# CTRL_MODULE_CORE register map
Vendor: Texas Instruments
Peripheral module from a debugger description file (folder omap5430_ES2_PUBLIC).
Registers are 32-bit, read-only, reset 0x0 unless marked. A register's access mark holds for its fields unless they carry their own. Offsets are as the file gives them; lines under a group give offsets from that group; [hi:lo] are bit positions; {n}, {i} and the like mark numbered series; 'fields as' and 'values as' point back to an identical list; <NAME> marks a mode.

## CTRL_MODULE_CORE (part 1 of 2)
0x00 CONTROL_CORE_REVISION reset not defined — Control module revision identifier Access conditions. Read: unrestricted, Write: unrestricted
  [31:0] REVISON — IP Revision enum=hl_scheme . enum=legacy_scheme .
0x04 CONTROL_CORE_HWINFO — Information about the IP module hardware configuration i.e. typically the module HDL generics (if any). Access conditions. Read: unrestricted, Write: unrestricted
  [31:0] IP_HWINFO — IP-module dependent
0x10 CONTROL_CORE_SYSCONFIG access per field reset 0x8 — Access conditions. Read: unrestricted, Write: unrestricted
  [3:2] IP_SYSCONFIG_IDLEMODE rw — RESERVED (not used).
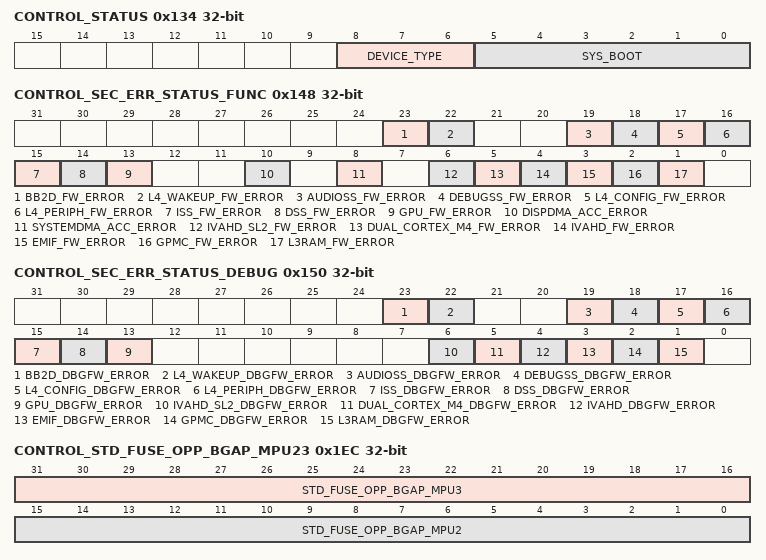
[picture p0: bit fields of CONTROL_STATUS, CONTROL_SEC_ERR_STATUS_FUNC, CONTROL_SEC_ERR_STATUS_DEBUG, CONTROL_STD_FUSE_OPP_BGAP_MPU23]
0x134 CONTROL_STATUS — Control Module Status Register Access conditions. Read: unrestricted, Write: unrestricted
  [8:6] DEVICE_TYPE — Device type captured at reset time Device type value sampled at power-on reset. . .
    3=dev_gp (General Purpose (GP))
  [5:0] SYS_BOOT — Sys.Boot pins state captured at reset time Sys.Boot pin values sampled at power-on reset
0x148 CONTROL_SEC_ERR_STATUS_FUNC — Firewall Error Status functional Register Access conditions. Read Only
  [23] BB2D_FW_ERROR — BB2D firewall
    0=no_bb2d_fw_error (No error from firewall); 1=bb2d_fw_error (Error from firewall)
  [22] L4_WAKEUP_FW_ERROR — L4 wakeup firewall
    0=no_l4wkup_fw_error (No error from firewall); 1=l4wkup_fw_error (Error from firewall)
  [19] AUDIOSS_FW_ERROR — AUDIOSS firewall
    0=no_audioss_init_fw_err (No error from firewall); 1=audioss_init_fw_err (Error from firewall)
  [18] DEBUGSS_FW_ERROR — DebugSS firewall
    0=no_debugss_fw_err (No error from firewall); 1=debugss_fw_err (Error from firewall)
  [17] L4_CONFIG_FW_ERROR — L4 config firewall
    0=no_l4config_fw_err (No error from firewall); 1=l4config_fw_err (Error from firewall)
  [16] L4_PERIPH_FW_ERROR — L4 periph firewall
    0=no_l4periph_fw_err (No error from firewall); 1=l4periph_fw_err (Error from firewall)
  [15] ISS_FW_ERROR — ISS firewall
    0=no_iss_fw_err (No error from firewall); 1=iss_fw_err (Error from firewall)
  [14] DSS_FW_ERROR — DSS firewall
    0=no_dss_fw_err (No error from firewall); 1=dss_fw_err (Error from firewall)
  [13] GPU_FW_ERROR — GPU firewall
    0=no_gpu_fw_err (No error from firewall); 1=gpu_fw_err (Error from firewall)
  [10] DISPDMA_ACC_ERROR — DISPDMA target firewall
    0=no_dispdma_target_fw_err (No error from firewall); 1=dispdma_target_fw_err (Error from firewall)
  [8] SYSTEMDMA_ACC_ERROR — SYSTEMDMA target firewall
    0=no_systemdma_target_fw_err (No error from firewall); 1=systemdma_target_fw_err (Error from firewall)
  [6] IVAHD_SL2_FW_ERROR — IVAHD SL2 firewall
    0=no_ivahd_sl2_fw_err (No error from firewall); 1=ivahd_sl2_fw_err (Error from firewall)
  [5] DUAL_CORTEX_M4_FW_ERROR — Dual Cortex M4 firewall
    0=no_ducati_fw_err (No error from firewall); 1=ducati_fw_err (Error from firewall)
  [4] IVAHD_FW_ERROR — IVAHD firewall
    0=no_ivahd_fw_err (No error from firewall); 1=ivahd_fw_err (Error from firewall)
  [3] EMIF_FW_ERROR — EMIF firewall
    0=no_emif_fw_err (No error from firewall); 1=emif_fw_err (Error from firewall)
  [2] GPMC_FW_ERROR — GPMC firewall
    0=no_gpmc_fw_err (No error from firewall); 1=gpmc_fw_err (Error from firewall)
  [1] L3RAM_FW_ERROR — L3RAM firewall
    0=no_l3ram_fw_err (No error from firewall); 1=l3ram_fw_err (Error from firewall)
0x150 CONTROL_SEC_ERR_STATUS_DEBUG access not given — Firewall Error Status debug Register. Access conditions. Read: unrestricted, Write: unrestricted
  [23] BB2D_DBGFW_ERROR — BB2D debug firewall (access RW W1toClr)
    values as CONTROL_SEC_ERR_STATUS_FUNC.BB2D_FW_ERROR
  [22] L4_WAKEUP_DBGFW_ERROR — L4 wakeup debug firewall (access RW W1toClr)
    values as CONTROL_SEC_ERR_STATUS_FUNC.L4_WAKEUP_FW_ERROR
  [19] AUDIOSS_DBGFW_ERROR — AUDIOSS debug firewall (access RW W1toClr)
    values as CONTROL_SEC_ERR_STATUS_FUNC.AUDIOSS_FW_ERROR
  [18] DEBUGSS_DBGFW_ERROR — DebugSS debug firewall (access RW W1toClr)
    values as CONTROL_SEC_ERR_STATUS_FUNC.DEBUGSS_FW_ERROR
  [17] L4_CONFIG_DBGFW_ERROR — L4 config debug firewall (access RW W1toClr)
    values as CONTROL_SEC_ERR_STATUS_FUNC.L4_CONFIG_FW_ERROR
  [16] L4_PERIPH_DBGFW_ERROR — L4 periph debug firewall (access RW W1toClr)
    values as CONTROL_SEC_ERR_STATUS_FUNC.L4_PERIPH_FW_ERROR
  [15] ISS_DBGFW_ERROR — ISS debug firewall (access RW W1toClr)
    values as CONTROL_SEC_ERR_STATUS_FUNC.ISS_FW_ERROR
  [14] DSS_DBGFW_ERROR — DSS debug firewall (access RW W1toClr)
    values as CONTROL_SEC_ERR_STATUS_FUNC.DSS_FW_ERROR
  [13] GPU_DBGFW_ERROR — GPU debug firewall (access RW W1toClr)
    values as CONTROL_SEC_ERR_STATUS_FUNC.GPU_FW_ERROR
  [6] IVAHD_SL2_DBGFW_ERROR — IVAHD SL2 debug firewall (access RW W1toClr)
    values as CONTROL_SEC_ERR_STATUS_FUNC.IVAHD_SL2_FW_ERROR
  [5] DUAL_CORTEX_M4_DBGFW_ERROR — Dual Cortex M4 debug firewall (access RW W1toClr)
    values as CONTROL_SEC_ERR_STATUS_FUNC.DUAL_CORTEX_M4_FW_ERROR
  [4] IVAHD_DBGFW_ERROR — IVAHD debug firewall (access RW W1toClr)
    values as CONTROL_SEC_ERR_STATUS_FUNC.IVAHD_FW_ERROR
  [3] EMIF_DBGFW_ERROR — EMIF debug firewall (access RW W1toClr)
    values as CONTROL_SEC_ERR_STATUS_FUNC.EMIF_FW_ERROR
  [2] GPMC_DBGFW_ERROR — GPMC debug firewall (access RW W1toClr)
    values as CONTROL_SEC_ERR_STATUS_FUNC.GPMC_FW_ERROR
  [1] L3RAM_DBGFW_ERROR — L3RAM debug firewall (access RW W1toClr)
    values as CONTROL_SEC_ERR_STATUS_FUNC.L3RAM_FW_ERROR
0x15C CONTROL_FORCEWRNP access per field — FORCE WRITE NON POSTED Access conditions. Read: unrestricted, Write: unrestricted
  [0] MPU_FORCEWRNP rw — Force mpu write non posted
    0=disable force wrnp; 1=enable (force wrnp)
{0x194+4i} CONTROL_STD_FUSE_OPP_VDD_MM_{i} (i=0..5) — Standard Fuse OPP VDD_MM [{32i+31}:{32i}]. Register shows part of the chip eFuse configuration on the OCP interface. Reading at the address of one of these registers provides a direct view into a part of the eFuse chain. Access conditions. Read: unrestricted, Write: unrestricted
  [31:0] STD_FUSE_OPP_VDD_MM_{i}
{0x1AC+4i} CONTROL_STD_FUSE_OPP_VDD_MPU_{i} (i=0..7) — Standard Fuse OPP VDD_MPU [{32i+31}:{32i}]. Register shows part of the chip eFuse configuration on the OCP interface. Reading at the address of one of these registers provides a direct view into a part of the eFuse chain. Access conditions. Read: unrestricted, Write: unrestricted
  [31:0] STD_FUSE_OPP_VDD_MPU_{i}
{0x1CC+4i} CONTROL_STD_FUSE_OPP_VDD_CORE_{i} (i=0..4) — Standard Fuse OPP VDD_CORE [{32i+31}:{32i}]. Register shows part of the chip eFuse configuration on the OCP interface. Reading at the address of one of these registers provides a direct view into a part of the eFuse chain. Access conditions. Read: unrestricted, Write: unrestricted
  [31:0] STD_FUSE_OPP_VDD_CORE_{i}
0x1E0 CONTROL_STD_FUSE_OPP_BGAP_MM — Standard Fuse OPP BGAP MM. Register shows part of the chip eFuse configuration. Reading at the address of one of these registers provides a direct view into a part of the eFuse chain. Access conditions. Read: unrestricted, Write: unrestricted
  [31:0] STD_FUSE_OPP_BGAP_MM
0x1E4 CONTROL_STD_FUSE_OPP_BGAP_MPU — Standard Fuse OPP BGAP BGAP. Register shows part of the chip eFuse configuration. Reading at the address of one of these registers provides a direct view into a part of the eFuse chain. Access conditions. Read: unrestricted, Write: unrestricted
  [31:0] STD_FUSE_OPP_BGAP_MPU
0x1E8 CONTROL_STD_FUSE_OPP_BGAP_CORE — Standard Fuse OPP BGAP CORE. Register shows part of the chip eFuse configuration. Reading at the address of one of these registers provides a direct view into a part of the eFuse chain. Access conditions. Read: unrestricted, Write: unrestricted
  [31:0] STD_FUSE_OPP_BGAP_CORE
0x1EC CONTROL_STD_FUSE_OPP_BGAP_MPU23 — Standard Fuse OPP BGAP MPU3. Register shows part of the chip eFuse configuration. Reading at the address of one of these registers provides a direct view into a part of the eFuse chain. Access conditions. Read: unrestricted, Write: unrestricted
  [31:16] STD_FUSE_OPP_BGAP_MPU3, [15:0] STD_FUSE_OPP_BGAP_MPU2
0x200 CONTROL_STD_FUSE_DIE_ID_0 — Die ID Register - Part 0. Register shows part of the chip eFuse configuration. Reading at the address of one of these registers provides a direct view into a part of the eFuse chain. Access conditions. Read: unrestricted, Write: unrestricted
  [31:0] STD_FUSE_DIE_ID_0
{0x204+4i} CONTROL_STD_FUSE_DIE_ID_{i} (i=1..3) — Die ID Register - Part {i}. Register shows part of the chip eFuse configuration. Reading at the address of one of these registers provides a direct view into a part of the eFuse chain. For more information, see OMAP543x Family and Device Identification Access conditions. Read: unrestricted, Write: unrestricted
  [31:0] STD_FUSE_DIE_ID_{i}
0x214 CONTROL_STD_FUSE_PROD_ID — Prod ID Register - Part 0. Register shows part of the chip eFuse configuration. Reading at the address of one of these registers provides a direct view into a part of the eFuse chain. Access conditions. Read: unrestricted, Write: unrestricted
  [31:0] STD_FUSE_PROD_ID
0x218 CONTROL_STD_FUSE_CONF_ID_0 — Standard Fuse conf [31:0]. Register shows part of the chip eFuse configuration. Reading at the address of one of these registers provides a direct view into a part of the eFuse chain. Access conditions. Read: unrestricted, Write: unrestricted
  [31:0] STD_FUSE_CONF_ID_0
0x21C CONTROL_STD_FUSE_CONF_ID_1 — Standard Fuse conf [63:32]. Register shows part of the chip eFuse configuration. Reading at the address of one of these registers provides a direct view into a part of the eFuse chain. Access conditions. Read: unrestricted, Write: unrestricted
  [31:0] STD_FUSE_CONF_ID_1
{0x220+4i} CONTROL_STD_FUSE_MPK_{i} (i=0..7) — Standard Fuse keys. Root_public_key_hash [{32i+31}:{32i}]. Register shows part of the chip eFuse configuration on the OCP interface. Reading at the address of one of these registers provides a direct view into a part of the eFuse chain. Access conditions. Read: unrestricted, Write: unrestricted
  [31:0] STD_FUSE_MPK_{i}
{0x240+4i} CONTROL_STD_FUSE_OPP_VDD_MM_LVT_{i} (i=0..5) — Standard Fuse LVT OPP VDD_MM [{32i+31}:{32i}]. Register shows part of the chip eFuse configuration. Reading at the address of one of these registers provides a direct view into a part of the eFuse chain. Access conditions. Read: unrestricted, Write: unrestricted
  [31:0] STD_FUSE_OPP_VDD_MM_LVT_{i}
{0x258+4i} CONTROL_STD_FUSE_OPP_VDD_MPU_LVT_{i} (i=0..5) — Standard Fuse LVT OPP VDD_MPU [{32i+31}:{32i}]. Register shows part of the chip eFuse configuration. Reading at the address of one of these registers provides a direct view into a part of the eFuse chain. Access conditions. Read: unrestricted, Write: unrestricted
  [31:0] STD_FUSE_OPP_VDD_MPU_LVT_{i}
0x270 CONTROL_STD_FUSE_OPP_VDD_MPU_LVT_6 — Standard Fuse LVT OPP VDD_MPU [223:192]. Register shows part of the chip eFuse configuration on the OCP interface. Reading at the address of one of these registers provides a direct view into a part of the eFuse chain. Access conditions. Read: unrestricted, Write: unrestricted
  [31:0] STD_FUSE_OPP_VDD_MPU_LVT_6
0x274 CONTROL_STD_FUSE_OPP_VDD_MPU_LVT_7 — Standard Fuse LVT OPP VDD_MPU [255:224]. Register shows part of the chip eFuse configuration. Reading at the address of one of these registers provides a direct view into a part of the eFuse chain. Access conditions. Read: unrestricted, Write: unrestricted
  [31:0] STD_FUSE_OPP_VDD_MPU_LVT_7
0x2BC CONTROL_CUST_FUSE_SWRV_0 — Customer Fuse keys. Software Version Control [031:000] (16 bits upper Redundant field) [FIELD OVERFLOW]. Register shows part of the chip eFuse configuration on the OCP interface. Reading at the address of one of these registers provides a direct view into a part of the eFuse chain. Access conditions. Read: unrestricted, Write: unrestricted
  [31:0] CUST_FUSE_SWRV_0
0x2C0 CONTROL_CUST_FUSE_SWRV_1 — Customer Fuse keys. Software Version Control [063:032] (16 bits upper Redundant field) [FIELD F]. Register shows part of the chip eFuse configuration on the OCP interface. Reading at the address of one of these registers provides a direct view into a part of the eFuse chain. Access conditions. Read: unrestricted, Write: unrestricted
  [31:0] CUST_FUSE_SWRV_1
0x2C4 CONTROL_CUST_FUSE_SWRV_2 — Customer Fuse keys. Software Version Control [095:064] (16 bits upper Redundant field) [FIELD E]. Register shows part of the chip eFuse configuration on the OCP interface. Reading at the address of one of these registers provides a direct view into a part of the eFuse chain. Access conditions. Read: unrestricted, Write: unrestricted
  [31:0] CUST_FUSE_SWRV_2
0x2C8 CONTROL_CUST_FUSE_SWRV_3 — Customer Fuse keys. Software Version Control [127:096] (16 bits upper Redundant field) [FIELD D]. Register shows part of the chip eFuse configuration on the OCP interface. Reading at the address of one of these registers provides a direct view into a part of the eFuse chain. Access conditions. Read: unrestricted, Write: unrestricted
  [31:0] CUST_FUSE_SWRV_3
0x2CC CONTROL_CUST_FUSE_SWRV_4 — Customer Fuse keys. Software Version Control [159:127] (16 bits upper Redundant field) [FIELD C]. Register shows part of the chip eFuse configuration on the OCP interface. Reading at the address of one of these registers provides a direct view into a part of the eFuse chain. Access conditions. Read: unrestricted, Write: unrestricted
  [31:0] CUST_FUSE_SWRV_4
0x2D0 CONTROL_CUST_FUSE_SWRV_5 — Customer Fuse keys. Software Version Control [191:160] (16 bits upper Redundant field) [FIELD B]. Register shows part of the chip eFuse configuration on the OCP interface. Reading at the address of one of these registers provides a direct view into a part of the eFuse chain. Access conditions. Read: unrestricted, Write: unrestricted
  [31:0] CUST_FUSE_SWRV_5
0x2D4 CONTROL_CUST_FUSE_SWRV_6 — Customer Fuse keys. Software Version Control [223:192] (16 bits upper Redundant field) [FIELD A]. Register shows part of the chip eFuse configuration on the OCP interface. Reading at the address of one of these registers provides a direct view into a part of the eFuse chain. Access conditions. Read: unrestricted, Write: unrestricted
  [31:0] CUST_FUSE_SWRV_6
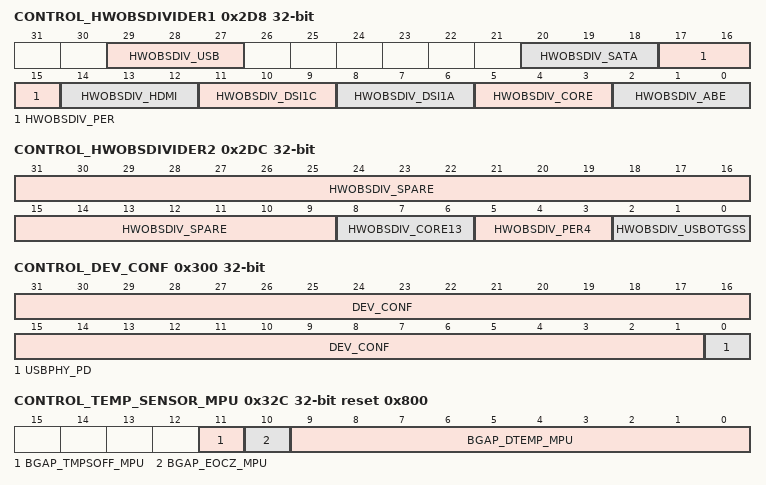
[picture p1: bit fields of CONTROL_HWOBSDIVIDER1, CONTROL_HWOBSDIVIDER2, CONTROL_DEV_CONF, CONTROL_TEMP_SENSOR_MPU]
0x2D8 CONTROL_HWOBSDIVIDER1 access per field — Divider selection register1. Access conditions. Read: unrestricted, Write: unrestricted
  [all] fields
    6=div32 (input is divided by 32); 1=div1 (input is divided by 1); 7=div64 (input is divided by 64); 0=noop (output is 0); 2=div2 (input is divided by 2); 4=div8 (input is divided by 8); 5=div16 (input is divided by 16); 3=div4 (input is divided by 4)
  [29:27] HWOBSDIV_USB rw — Control USB DPLL divider
  [20:18] HWOBSDIV_SATA rw — Control SATA DPLL divider
  [17:15] HWOBSDIV_PER rw — Control PER DPLL divider
  [14:12] HWOBSDIV_HDMI rw — Control HDMI DPLL divider
  [11:9] HWOBSDIV_DSI1C rw — Control DSI1C DPLL divider
  [8:6] HWOBSDIV_DSI1A rw — Control DSI1A DPLL divider
  [5:3] HWOBSDIV_CORE rw — Control CORE DPLL divider
  [2:0] HWOBSDIV_ABE rw — Control ABE DPLL divider
0x2DC CONTROL_HWOBSDIVIDER2 rw — Divider selection register2. Access conditions. Read: unrestricted, Write: unrestricted
  [31:9] HWOBSDIV_SPARE — Spare, can be used to control resources
  [8:6] HWOBSDIV_CORE13 — Control CORE13 divider
    values as the fields of CONTROL_HWOBSDIVIDER1
  [5:3] HWOBSDIV_PER4 — Control PER4 divider
    values as the fields of CONTROL_HWOBSDIVIDER1
  [2:0] HWOBSDIV_USBOTGSS — Control USBOTGSS DPLL divider
    values as the fields of CONTROL_HWOBSDIVIDER1
0x300 CONTROL_DEV_CONF rw — Device configuration register. Access conditions. Read: unrestricted, Write: unrestricted
  [31:1] DEV_CONF — Spare bits for device configuration.
  [0] USBPHY_PD — Power down entire USB phy (data, common module and UTMI). Controls USB2PHYCORE.PD pin.
    0=NormalOperation; 1=Power down the USB PHY
0x304 CONTROL_DSP_BOOTADDR rw reset 0x20000000 — DSP boot loader physical address Access conditions. Read: unrestricted, Write: unrestricted
  [31:10] DSP_BOOT_LOAD_ADDR — DSP boot loader physical address This index addresses a 4kbytes page
0x32C CONTROL_TEMP_SENSOR_MPU reset 0x800 — Control VBGAPTS temperature sensor and thermal comparator shutdown register Access conditions. Read: unrestricted, Write: unrestricted
  [11] BGAP_TMPSOFF_MPU — Temperature sensor and thermal shutdown mode.
  [10] BGAP_EOCZ_MPU — ADC End of Conversion. Active low, when CTRL_TEMP(9:0) is valid.
  [9:0] BGAP_DTEMP_MPU — Temperature data from the ADC. Valid if EOCZ is low.
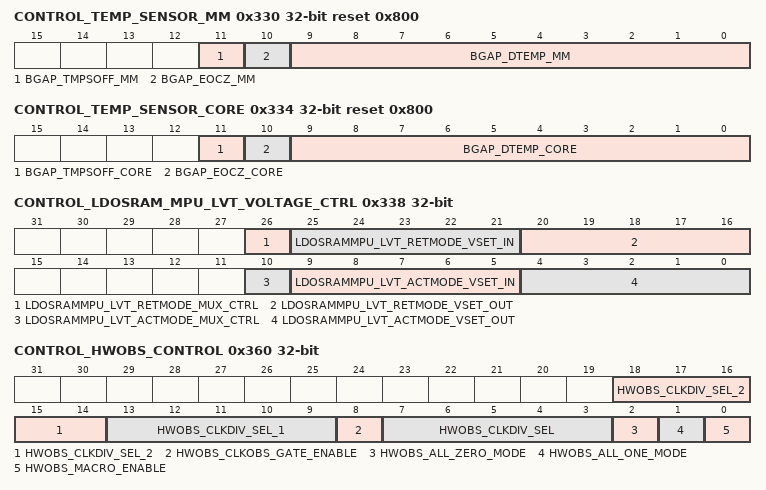
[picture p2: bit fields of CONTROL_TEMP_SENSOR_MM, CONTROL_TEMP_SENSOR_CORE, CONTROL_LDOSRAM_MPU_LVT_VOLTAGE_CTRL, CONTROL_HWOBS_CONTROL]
0x330 CONTROL_TEMP_SENSOR_MM reset 0x800 — Control VBGAPTS temperature sensor and thermal comparator shutdown register Access conditions. Read: unrestricted, Write: unrestricted
  [11] BGAP_TMPSOFF_MM — Temperature sensor and thermal shutdown mode.
  [10] BGAP_EOCZ_MM — ADC End of Conversion. Active low, when CTRL_TEMP(9:0) is valid.
  [9:0] BGAP_DTEMP_MM — Temperature data from the ADC. Valid if EOCZ is low.
0x334 CONTROL_TEMP_SENSOR_CORE reset 0x800 — Control VBGAPTS temperature sensor and thermal comparator shutdown register Access conditions. Read: unrestricted, Write: unrestricted
  [11] BGAP_TMPSOFF_CORE — Temperature sensor and thermal shutdown mode.
  [10] BGAP_EOCZ_CORE — ADC End of Conversion. Active low, when CTRL_TEMP(9:0) is valid.
  [9:0] BGAP_DTEMP_CORE — Temperature data from the ADC. Valid if EOCZ is low.
0x338 CONTROL_LDOSRAM_MPU_LVT_VOLTAGE_CTRL access per field — MPU LVT SRAM LDO Control register Access conditions. Read: unrestricted, Write: unrestricted
  [26] LDOSRAMMPU_LVT_RETMODE_MUX_CTRL rw — Override control of EFUSE Retention Mode Voltage value
    0=efuse value is used; 1=ocp (override value is used)
  [25:21] LDOSRAMMPU_LVT_RETMODE_VSET_IN ro — EFUSE Retention Mode Voltage value (vset[9:5])
  [20:16] LDOSRAMMPU_LVT_RETMODE_VSET_OUT rw — Override value for Retention Mode Voltage
  [10] LDOSRAMMPU_LVT_ACTMODE_MUX_CTRL rw — Override control of EFUSE Active Mode Voltage value
    0=efuse value is used; 1=ocp (override value is used)
  [9:5] LDOSRAMMPU_LVT_ACTMODE_VSET_IN ro — EFUSE Active Mode Voltage value (vset[4:0])
  [4:0] LDOSRAMMPU_LVT_ACTMODE_VSET_OUT rw — Override value for Active Mode Voltage value
0x358 CONTROL_CORTEX_M4_MMUADDRTRANSLTR access per field — CORTEX_M4 reg Access conditions. Read: unrestricted, Write: unrestricted
  [19:0] CORTEX_M4_MMUADDRTRANSLTR rw — Used to save the mmu address boot
0x35C CONTROL_CORTEX_M4_MMUADDRLOGICTR access per field — Access conditions. Read: unrestricted, Write: unrestricted
  [19:0] CORTEX_M4_MMUADDRLOGICTR rw
0x360 CONTROL_HWOBS_CONTROL access per field — HW observability control. This register enables or disables HW observability outputs (to save power primarily) Access conditions. Read: unrestricted, Write: unrestricted
  [18:14] HWOBS_CLKDIV_SEL_2 rw — Clock divider selection on po_hwobs(2).
    8=div8 (output is divided by 8); 1=nodiv (output is not divided); 4=div4 (output is divided by 4); 16=div16 (output is divided by 16); 2=div2 (output is divided by 2)
  [13:9] HWOBS_CLKDIV_SEL_1 rw — Clock divider selection on po_hwobs(1).
    values as HWOBS_CLKDIV_SEL_2
  [8] HWOBS_CLKOBS_GATE_ENABLE rw — Used to gate clk observable signals at the output of the DPLLs in order to save power
  [7:3] HWOBS_CLKDIV_SEL rw — Clock divider selection on po_hwobs(0).
    values as HWOBS_CLKDIV_SEL_2
  [2] HWOBS_ALL_ZERO_MODE rw — Used to gate observable signals. When set all outputs are set to zero (can be used to check the path from HW observability to external pads).
    0=disabled (hw observability ports are not gated); 1=enabled (hw observability ports are all set to 0)
  [1] HWOBS_ALL_ONE_MODE rw — Used to gate observable signals. When set all outputs are set to one (can be used to check the path from HW observability to external pads).
    0=disabled (hw observability ports are not gated); 1=enabled (hw observability ports are all set to 1)
  [0] HWOBS_MACRO_ENABLE rw — Used to gate observable signals coming from macros using the 32-bit HWOBS bus definition. When deasserted all outputs of the HWOBS busdef are set to zero.
    0=disabled (hw observability ports from macros are gated and set to zero); 1=enabled (hw observability ports from macros are not gated)
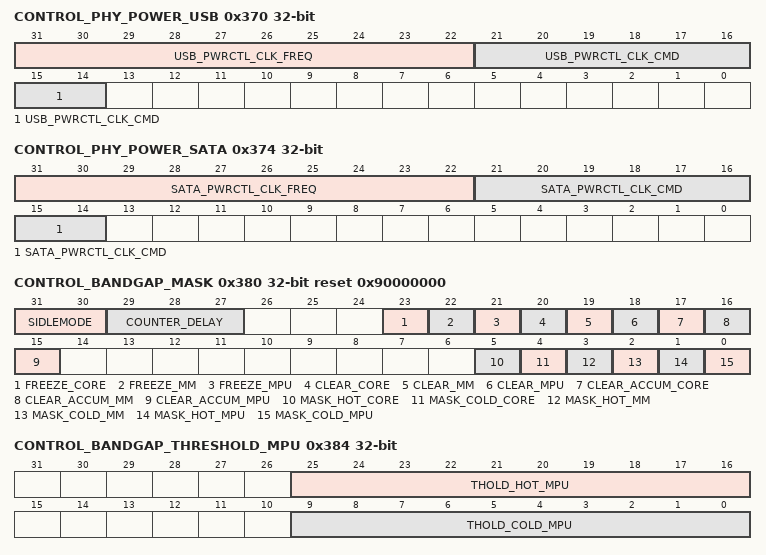
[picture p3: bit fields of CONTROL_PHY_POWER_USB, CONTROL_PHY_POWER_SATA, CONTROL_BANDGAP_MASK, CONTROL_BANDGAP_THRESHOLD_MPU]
0x370 CONTROL_PHY_POWER_USB access per field — phy_power_usb Access conditions. Read: unrestricted, Write: unrestricted
  [31:22] USB_PWRCTL_CLK_FREQ rw — Indicates the frequency of REF_CLK 0x26: If SYSCLK = 38.4 MHz 0x1A: If SYSCLK = 26.0 MHz 0x13: If SYSCLK = 19.2 MHz 0x10: If SYSCLK = 16.8 MHz 0x0C: If SYSCLK = 12.0 MHz
  [21:14] USB_PWRCTL_CLK_CMD rw — Powers up/down the USB3_PHY_TX and USB3_PHY_RX modules.
0x374 CONTROL_PHY_POWER_SATA access per field — phy_power_sata Access conditions. Read: unrestricted, Write: unrestricted
  [31:22] SATA_PWRCTL_CLK_FREQ rw — Indicate the frequency of REF_CLK 0x26: If SYSCLK = 38.4 MHz 0x1A: If SYSCLK = 26.0 MHz 0x13: If SYSCLK = 19.2 MHz 0x10: If SYSCLK = 16.8 MHz 0x0C: If SYSCLK = 12.0 MHz
  [21:14] SATA_PWRCTL_CLK_CMD rw — Powers up/down the SATA_PHY_TX and SATA_PHY_RX modules 0x0: powers down SATA_PHY_TX and SATA_PHY_RX 0x1: powers up the SATA_PHY_RX only. 0x2: powers up the SATA_PHY_TX only. 0x3: simultaneously powers up the SATA_PHY_RX and the SATA_PHY_TX
0x380 CONTROL_BANDGAP_MASK access per field reset 0x90000000 — bgap_mask Access conditions. Read: unrestricted, Write: unrestricted
  [31:30] SIDLEMODE rw — sidlemode for bandgap
    0=NoIdle; 1=ForceIdle; 3=NoFunc (Reserved); 2=SmartIdle
  [29:27] COUNTER_DELAY rw
    1=c_1ms (Delay of 1ms); 0=c_imediat (Immediate); 2=c_10ms (Delay of 10ms); 4=c_250ms (Delay of 250ms); 5=c_500ms (Delay of 500ms); 3=c_100ms (Delay of 100ms)
  [23] FREEZE_CORE rw — Freeze the FIFO CORE
    0=No operation; 1=Freeze the FIFO
  [22] FREEZE_MM rw — Freeze the FIFO MM
    0=No operation; 1=Freeze the FIFO
  [21] FREEZE_MPU rw — Freeze the FIFO MPU
    0=No operation; 1=Freeze the FIFO
  [20] CLEAR_CORE rw — Reset the FIFO CORE
    0=No operation; 1=Reset the FIFO
  [19] CLEAR_MM rw — Reset the FIFO MM
    0=No operation; 1=Reset the FIFO
  [18] CLEAR_MPU rw — Reset the FIFO MPU
    0=No operation; 1=Reset the FIFO
  [17] CLEAR_ACCUM_CORE rw — Reset the accumulator CORE. Reset also the FIFO CORE
    0=No operation; 1=Reset the accumulator
  [16] CLEAR_ACCUM_MM rw — Reset the accumulator MM. Reset also the FIFO MM
    0=No operation; 1=Reset the accumulator
  [15] CLEAR_ACCUM_MPU rw — Reset the accumulator MPU. Reset also the FIFO MPU
    0=No operation; 1=Reset the accumulator
  [5] MASK_HOT_CORE rw — Mask for hot event CORE
    0=masked (hot event is masked); 1=unmasked (hot event is unmasked)
  [4] MASK_COLD_CORE rw — Mask for cold event CORE
    0=masked (cold event is masked); 1=unmasked (cold event is unmasked)
  [3] MASK_HOT_MM rw — Mask for hot event MM
    values as MASK_HOT_CORE
  [2] MASK_COLD_MM rw — Mask for cold event MM
    values as MASK_COLD_CORE
  [1] MASK_HOT_MPU rw — Mask for hot event MPU
    values as MASK_HOT_CORE
  [0] MASK_COLD_MPU rw — Mask for cold event MPU
    values as MASK_COLD_CORE
0x384 CONTROL_BANDGAP_THRESHOLD_MPU access per field — BGAP THRESHOLD MPU Access conditions. Read: unrestricted, Write: unrestricted
  [25:16] THOLD_HOT_MPU rw — alert value hot
  [9:0] THOLD_COLD_MPU rw — alert value cold
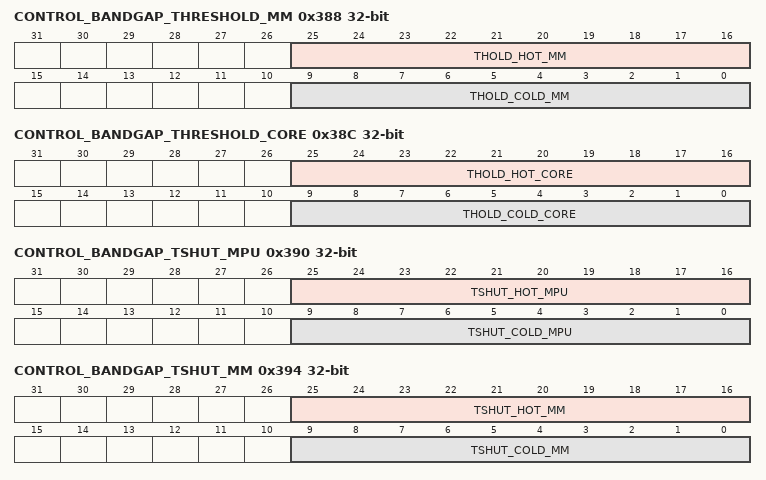
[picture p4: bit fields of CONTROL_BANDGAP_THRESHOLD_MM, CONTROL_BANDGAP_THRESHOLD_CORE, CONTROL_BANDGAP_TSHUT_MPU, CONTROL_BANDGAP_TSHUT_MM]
0x388 CONTROL_BANDGAP_THRESHOLD_MM access per field — BGAP THRESHOLD MM Access conditions. Read: unrestricted, Write: unrestricted
  [25:16] THOLD_HOT_MM rw — alert value hot
  [9:0] THOLD_COLD_MM rw — alert value cold
0x38C CONTROL_BANDGAP_THRESHOLD_CORE access per field — BGAP THRESHOLD CORE Access conditions. Read: unrestricted, Write: unrestricted
  [25:16] THOLD_HOT_CORE rw — alert value hot
  [9:0] THOLD_COLD_CORE rw — alert value cold
0x390 CONTROL_BANDGAP_TSHUT_MPU — BGAP TSHUT THRESHOLD MPU Access conditions. Read Only
  [25:16] TSHUT_HOT_MPU — tshut value hot
  [9:0] TSHUT_COLD_MPU — tshut value cold
0x394 CONTROL_BANDGAP_TSHUT_MM — BGAP TSHUT THRESHOLD MM Access conditions. Read Only
  [25:16] TSHUT_HOT_MM — tshut value hot
  [9:0] TSHUT_COLD_MM — tshut value cold
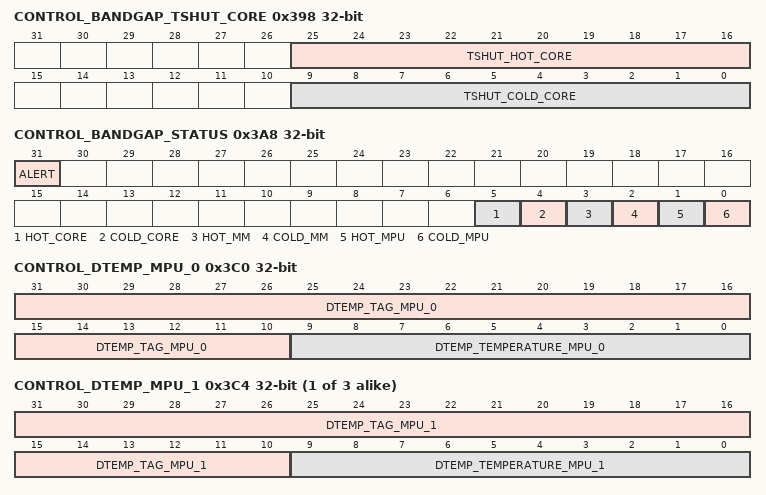
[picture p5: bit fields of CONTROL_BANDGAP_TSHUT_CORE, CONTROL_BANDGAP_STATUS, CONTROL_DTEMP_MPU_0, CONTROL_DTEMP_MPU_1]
0x398 CONTROL_BANDGAP_TSHUT_CORE — BGAP TSHUT THRESHOLD CORE Access conditions. Read Only
  [25:16] TSHUT_HOT_CORE — tshut value hot
  [9:0] TSHUT_COLD_CORE — tshut value cold
0x39C CONTROL_BANDGAP_CUMUL_DTEMP_MPU — BGAP TEMPERATURE ACCUMULATOR MPU Access conditions. Read: unrestricted, Write: unrestricted
  [31:0] CUMUL_DTEMP_MPU — temperature accumulator
0x3A0 CONTROL_BANDGAP_CUMUL_DTEMP_MM — BGAP TEMPERATURE ACCUMULATOR MM Access conditions. Read: unrestricted, Write: unrestricted
  [31:0] CUMUL_DTEMP_MM — temperature accumulator
0x3A4 CONTROL_BANDGAP_CUMUL_DTEMP_CORE — BGAP TEMPERATURE ACCUMULATOR CORE Access conditions. Read: unrestricted, Write: unrestricted
  [31:0] CUMUL_DTEMP_CORE — temperature accumulator
0x3A8 CONTROL_BANDGAP_STATUS — BGAP STATUS Access conditions. Read: unrestricted, Write: unrestricted
  [31] ALERT — Alert temperature when '1'
  [5] HOT_CORE — Event for hot temperature mpu bandgap when '1'
    1=event detected; 0=noevent (event not detected)
  [4] COLD_CORE — Event for cold temperature mpu bandgap when '1'
    1=event detected; 0=noevent (event not detected)
  [3] HOT_MM — Event for hot temperature mm bandgap when '1'
    1=event detected; 0=noevent (event not detected)
  [2] COLD_MM — Event for cold temperature mm bandgap when '1'
    1=event detected; 0=noevent (event not detected)
  [1] HOT_MPU — Event for hot temperature core bandgap when '1'
    1=event detected; 0=noevent (event not detected)
  [0] COLD_MPU — Event for cold temperature core bandgap when '1'
    1=event detected; 0=noevent (event not detected)
0x3AC CONTROL_SATA_EXT_MODE access per field — SATA EXTENDED MODE Access conditions. Read: unrestricted, Write: unrestricted
  [0] SATA_EXTENDED_MODE rw
    0=no extended mode; 1=extended mode
0x3C0 CONTROL_DTEMP_MPU_0 — TAGGED TEMPERATURE MPU DOMAIN. Most recent sample Access conditions. Read: unrestricted, Write: unrestricted
  [31:10] DTEMP_TAG_MPU_0 — tag. Indicate number of times in the bgap state machine.
  [9:0] DTEMP_TEMPERATURE_MPU_0 — temperature
{0x3C0+4i} CONTROL_DTEMP_MPU_{i} (i=1..3) — TAGGED TEMPERATURE MPU DOMAIN Access conditions. Read: unrestricted, Write: unrestricted
  [31:10] DTEMP_TAG_MPU_{i} — tag. Indicate number of times in the bgap state machine.
  [9:0] DTEMP_TEMPERATURE_MPU_{i} — temperature
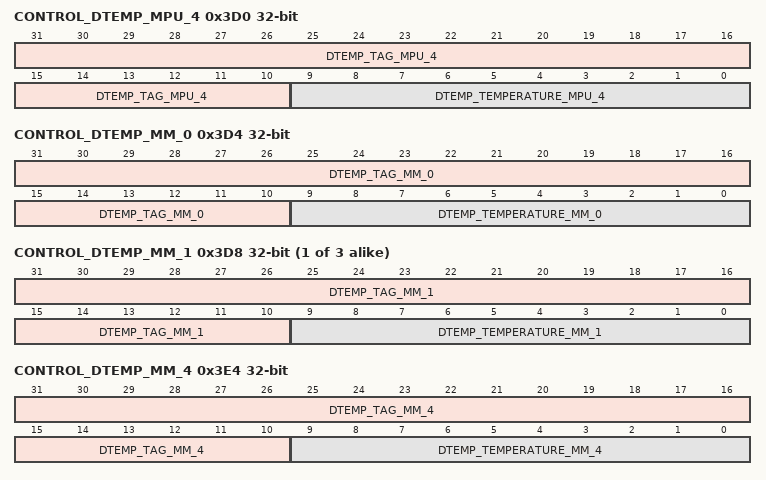
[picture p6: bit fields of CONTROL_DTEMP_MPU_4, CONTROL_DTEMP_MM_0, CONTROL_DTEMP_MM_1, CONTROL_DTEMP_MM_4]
0x3D0 CONTROL_DTEMP_MPU_4 — TAGGED TEMPERATURE MPU DOMAIN. Oldest sample Access conditions. Read: unrestricted, Write: unrestricted
  [31:10] DTEMP_TAG_MPU_4 — tag. Indicate number of times in the bgap state machine.
  [9:0] DTEMP_TEMPERATURE_MPU_4 — temperature
0x3D4 CONTROL_DTEMP_MM_0 — TAGGED TEMPERATURE MM DOMAIN. Most recent sample. Access conditions. Read: unrestricted, Write: unrestricted
  [31:10] DTEMP_TAG_MM_0 — tag. Indicate number of times in the bgap state machine.
  [9:0] DTEMP_TEMPERATURE_MM_0 — temperature
{0x3D4+4i} CONTROL_DTEMP_MM_{i} (i=1..3) — TAGGED TEMPERATURE MM DOMAIN Access conditions. Read: unrestricted, Write: unrestricted
  [31:10] DTEMP_TAG_MM_{i} — tag. Indicate number of times in the bgap state machine.
  [9:0] DTEMP_TEMPERATURE_MM_{i} — temperature
0x3E4 CONTROL_DTEMP_MM_4 — TAGGED TEMPERATURE MM DOMAIN. Oldest sample. Access conditions. Read: unrestricted, Write: unrestricted
  [31:10] DTEMP_TAG_MM_4 — tag. Indicate number of times in the bgap state machine.
  [9:0] DTEMP_TEMPERATURE_MM_4 — temperature
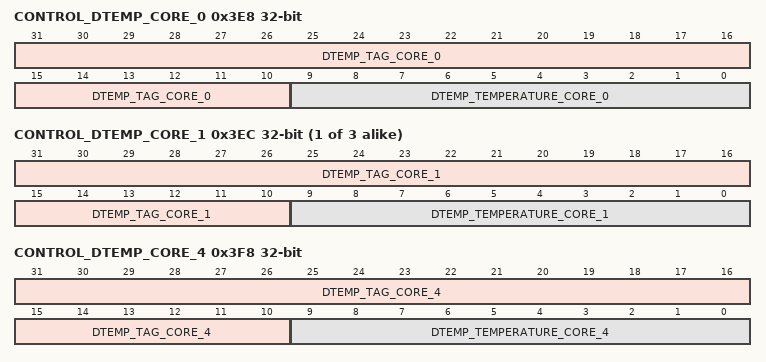
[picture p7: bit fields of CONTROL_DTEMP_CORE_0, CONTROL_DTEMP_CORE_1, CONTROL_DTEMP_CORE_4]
0x3E8 CONTROL_DTEMP_CORE_0 — TAGGED TEMPERATURE CORE DOMAIN. Most recent sample. Access conditions. Read: unrestricted, Write: unrestricted
  [31:10] DTEMP_TAG_CORE_0 — tag. Indicate number of times in the bgap state machine.
  [9:0] DTEMP_TEMPERATURE_CORE_0 — temperature
{0x3E8+4i} CONTROL_DTEMP_CORE_{i} (i=1..3) — TAGGED TEMPERATURE CORE DOMAIN Access conditions. Read: unrestricted, Write: unrestricted
  [31:10] DTEMP_TAG_CORE_{i} — tag. Indicate number of times in the bgap state machine.
  [9:0] DTEMP_TEMPERATURE_CORE_{i} — temperature
0x3F8 CONTROL_DTEMP_CORE_4 — TAGGED TEMPERATURE CORE DOMAIN. Oldest sample. Access conditions. Read: unrestricted, Write: unrestricted
  [31:10] DTEMP_TAG_CORE_4 — tag. Indicate number of times in the bgap state machine.
  [9:0] DTEMP_TEMPERATURE_CORE_4 — temperature
0x3FC CONTROL_OCPREG_SPARE rw — Spare Register Access conditions. Read: unrestricted, Write: unrestricted
  [31:0] OCPREG_SPARE — Spare register
0x400 CONTROL_DEBOBS_FINAL_MUX_SEL rw — Final mux select signal. It selects between core and wkup signal (controls external observability logic). Access conditions. Read: unrestricted, Write: unrestricted
  [31:0] SELECT — (Control external observability logic)
0x404 CONTROL_DEBOBS_OCPWP_SYS_EVENT_SEL access per field — Selection between debug module (0) or PRM (1) outputs for OCP WP (controls external observability logic). Access conditions. Read: unrestricted, Write: unrestricted
  [15:0] SELECT rw — (Control external observability logic)
0x408 CONTROL_DEBOBS_MMR_MPU access per field — MPU MMR register to control HW observability muxing inside mpu (controls external observability logic). Access conditions. Read: unrestricted, Write: unrestricted
  [3:0] SELECT rw — (Control external observability logic)
0x42C CONTROL_CONF_SDMA_REQ_SEL0 access per field — System DMA requests view channel 0 Access conditions. Read: unrestricted, Write: unrestricted
  [6:0] MULT rw — Select one of the following signals :
    {v}=MULT_I{v} (hwobs_sdma_dma_req_{v}) (v=0..126)
0x430 CONTROL_CONF_SDMA_REQ_SEL1 access per field reset 0x1 — System DMA requests view channel 1 Access conditions. Read: unrestricted, Write: unrestricted
  fields as CONTROL_CONF_SDMA_REQ_SEL0
0x434 CONTROL_CONF_SDMA_REQ_SEL2 access per field reset 0x2 — System DMA requests view channel 2 Access conditions. Read: unrestricted, Write: unrestricted
  fields as CONTROL_CONF_SDMA_REQ_SEL0
0x438 CONTROL_CONF_SDMA_REQ_SEL3 access per field reset 0x3 — System DMA requests view channel 3 Access conditions. Read: unrestricted, Write: unrestricted
  fields as CONTROL_CONF_SDMA_REQ_SEL0
0x440 CONTROL_CONF_CLK_SEL0 access per field — clk view channel 0 Access conditions. Read: unrestricted, Write: unrestricted
  [3:0] MULT rw — Select one of the following signals :
    6=MULT_I6 (hwobs_satadpll_clkout); 1=MULT_I1 (hwobs_abedpll_clkout); 10=MULT_I10 (Reserved); 7=MULT_I7 (hwobs_usbotgssdpll_clkout); 0=MULT_I0 (hwobs_coredpll_clkout); 2=MULT_I2 (hwobs_perdpll_clkout); 8=MULT_I8 (hwobs_usbdpll_clkout); 9=MULT_I9 (Reserved); 4=MULT_I4 (hwobs_dsi1cdpll_clkout); 5=MULT_I5 (hwobs_hdmidpll_clkout); 3=MULT_I3 (hwobs_dsi1adpll_clkout)
0x444 CONTROL_CONF_CLK_SEL1 access per field reset 0x1 — clk view channel 1 Access conditions. Read: unrestricted, Write: unrestricted
  fields as CONTROL_CONF_CLK_SEL0
